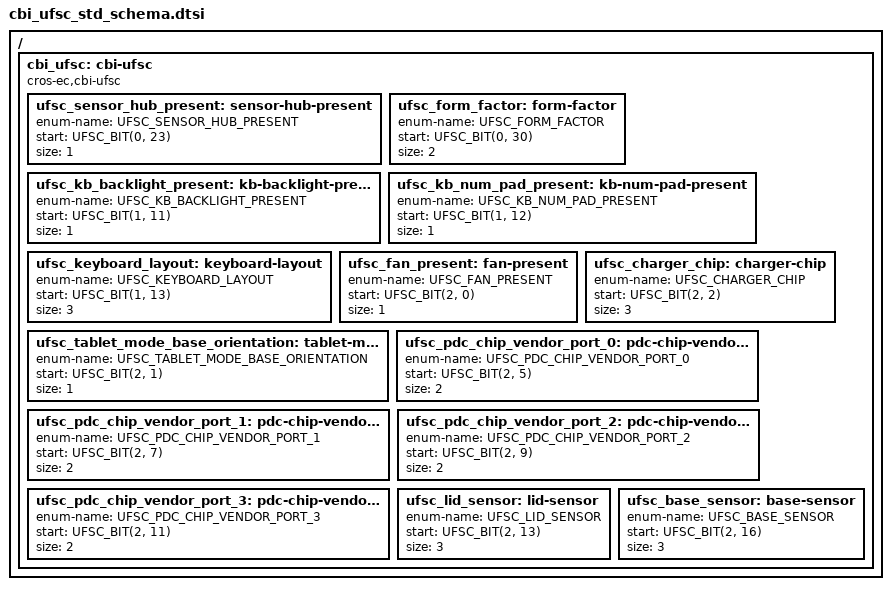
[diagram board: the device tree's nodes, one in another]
/* Copyright 2025 The ChromiumOS Authors
 * Use of this source code is governed by a BSD-style license that can be
 * found in the LICENSE file.
 */

#define UFSC_BIT(dword, bit) ((dword) * 32 + (bit))

/ {
	cbi_ufsc: cbi-ufsc {
		compatible = "cros-ec,cbi-ufsc";

		ufsc_sensor_hub_present: sensor-hub-present {
			enum-name = "UFSC_SENSOR_HUB_PRESENT";
			start = <UFSC_BIT(0, 23)>;
			size = <1>;
		};
		ufsc_form_factor: form-factor {
			enum-name = "UFSC_FORM_FACTOR";
			start = <UFSC_BIT(0, 30)>;
			size = <2>;
		};
		ufsc_kb_backlight_present: kb-backlight-present {
			enum-name = "UFSC_KB_BACKLIGHT_PRESENT";
			start = <UFSC_BIT(1, 11)>;
			size = <1>;
		};
		ufsc_kb_num_pad_present: kb-num-pad-present {
			enum-name = "UFSC_KB_NUM_PAD_PRESENT";
			start = <UFSC_BIT(1, 12)>;
			size = <1>;
		};
		ufsc_keyboard_layout: keyboard-layout {
			enum-name = "UFSC_KEYBOARD_LAYOUT";
			start = <UFSC_BIT(1, 13)>;
			size = <3>;
		};
		ufsc_fan_present: fan-present {
			enum-name = "UFSC_FAN_PRESENT";
			start = <UFSC_BIT(2, 0)>;
			size = <1>;
		};
		ufsc_tablet_mode_base_orientation: tablet-mode-base-orientation {
			enum-name = "UFSC_TABLET_MODE_BASE_ORIENTATION";
			start = <UFSC_BIT(2, 1)>;
			size = <1>;
		};
		ufsc_charger_chip: charger-chip {
			enum-name = "UFSC_CHARGER_CHIP";
			start = <UFSC_BIT(2, 2)>;
			size = <3>;
		};
		ufsc_pdc_chip_vendor_port_0: pdc-chip-vendor-port-0 {
			enum-name = "UFSC_PDC_CHIP_VENDOR_PORT_0";
			start = <UFSC_BIT(2, 5)>;
			size = <2>;
		};
		ufsc_pdc_chip_vendor_port_1: pdc-chip-vendor-port-1 {
			enum-name = "UFSC_PDC_CHIP_VENDOR_PORT_1";
			start = <UFSC_BIT(2, 7)>;
			size = <2>;
		};
		ufsc_pdc_chip_vendor_port_2: pdc-chip-vendor-port-2 {
			enum-name = "UFSC_PDC_CHIP_VENDOR_PORT_2";
			start = <UFSC_BIT(2, 9)>;
			size = <2>;
		};
		ufsc_pdc_chip_vendor_port_3: pdc-chip-vendor-port-3 {
			enum-name = "UFSC_PDC_CHIP_VENDOR_PORT_3";
			start = <UFSC_BIT(2, 11)>;
			size = <2>;
		};
		ufsc_lid_sensor: lid-sensor {
			enum-name = "UFSC_LID_SENSOR";
			start = <UFSC_BIT(2, 13)>;
			size = <3>;
		};
		ufsc_base_sensor: base-sensor {
			enum-name = "UFSC_BASE_SENSOR";
			start = <UFSC_BIT(2, 16)>;
			size = <3>;
		};
	};
};
